# FM33LC0XX register map
File version: 1.0
CPU: SC123, little endian, no MPU, no FPU, 3 interrupt priority bits
Registers are 32-bit, read-write, reset 0x0 unless marked. A register's access mark holds for its fields unless they carry their own. Offsets are from the block's base; [hi:lo] are bit positions; {n}, {i} and the like mark numbered series; 'fields as' and 'values as' point back to an identical list.

## USB — USB module information
Base 0x50000000
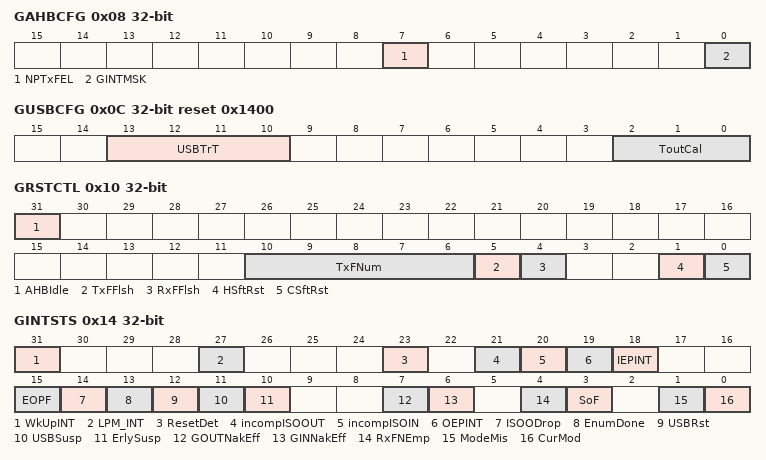
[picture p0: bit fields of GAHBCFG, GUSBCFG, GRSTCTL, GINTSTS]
0x08 GAHBCFG — USB AHB Global Config Register
  [7] NPTxFEL — NPTxFEL field description
  [0] GINTMSK — GINTMSK field description
0x0C GUSBCFG reset 0x1400 — USB Global Config Register
  [13:10] USBTrT — USBTrT field description
  [2:0] ToutCal — ToutCal field description
0x10 GRSTCTL — USB Global Reset Control Register
  [31] AHBIdle — AHBIdle field description
  [10:6] TxFNum — TxFNum field description
  [5] TxFFlsh — TxFFlsh field description
  [4] RxFFlsh — RxFFlsh field description
  [1] HSftRst — HSftRst field description
  [0] CSftRst — CSftRst field description
0x14 GINTSTS — USB Global Interrupt Status Register
  [31] WkUpINT — WkUpINT field description
  [27] LPM_INT — LPM_INT field description
  [23] ResetDet — ResetDet field description
  [21] incompISOOUT — incompISOOUT field description
  [20] incompISOIN — incompISOIN field description
  [19] OEPINT ro — OEPINT field description
  [18] IEPINT ro — IEPINT field description
  [15] EOPF — EOPF field description
  [14] ISOODrop — ISOODrop field description
  [13] EnumDone — EnumDone field description
  [12] USBRst — USBRst field description
  [11] USBSusp — USBSusp field description
  [10] ErlySusp — ErlySusp field description
  [7] GOUTNakEff ro — GOUTNakEff field description
  [6] GINNakEff ro — GINNakEff field description
  [4] RxFNEmp ro — RxFNEmp field description
  [3] SoF — SoF field description
  [1] ModeMis — ModeMis field description
  [0] CurMod ro — CurMod field description
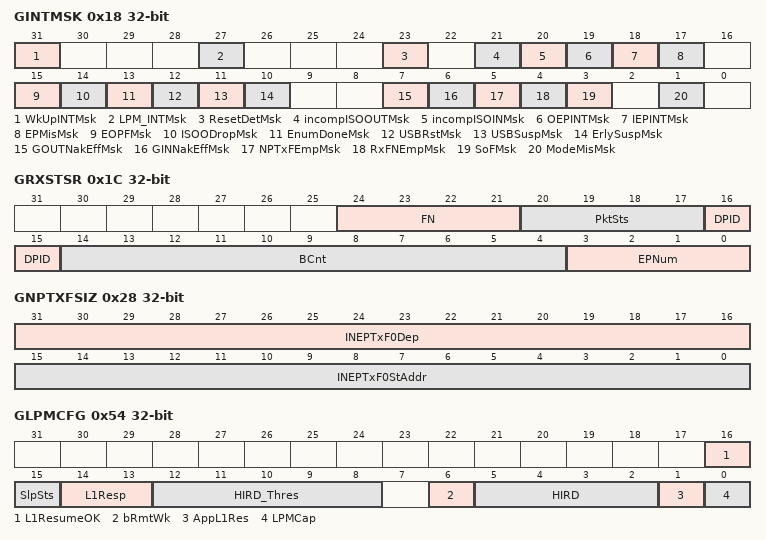
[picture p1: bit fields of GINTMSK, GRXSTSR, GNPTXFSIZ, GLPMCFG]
0x18 GINTMSK — USB Global Interrupt Mask Register
  [31] WkUpINTMsk — WkUpINTMsk field description
  [27] LPM_INTMsk — LPM_INTMsk field description
  [23] ResetDetMsk — ResetDetMsk field description
  [21] incompISOOUTMsk — incompISOOUTMsk field description
  [20] incompISOINMsk — incompISOINMsk field description
  [19] OEPINTMsk — OEPINTMsk field description
  [18] IEPINTMsk — IEPINTMsk field description
  [17] EPMisMsk — EPMisMsk field description
  [15] EOPFMsk — EOPFMsk field description
  [14] ISOODropMsk — ISOODropMsk field description
  [13] EnumDoneMsk — EnumDoneMsk field description
  [12] USBRstMsk — USBRstMsk field description
  [11] USBSuspMsk — USBSuspMsk field description
  [10] ErlySuspMsk — ErlySuspMsk field description
  [7] GOUTNakEffMsk — GOUTNakEffMsk field description
  [6] GINNakEffMsk — GINNakEffMsk field description
  [5] NPTxFEmpMsk — NPTxFEmpMsk field description
  [4] RxFNEmpMsk — RxFNEmpMsk field description
  [3] SoFMsk — SoFMsk field description
  [1] ModeMisMsk — ModeMisMsk field description
0x1C GRXSTSR — USB Receive Status Debug Read Register
  [24:21] FN ro — FN field description
  [20:17] PktSts ro — PktSts field description
  [16:15] DPID ro — DPID field description
  [14:4] BCnt ro — BCnt field description
  [3:0] EPNum ro — EPNum field description
0x24 GRXFSIZ — USB Receive FIFO size Register
  [15:0] RxFDep ro — RxFDep field description
0x28 GNPTXFSIZ — USB Non-Periodic Transmit FIFO size Register
  [31:16] INEPTxF0Dep ro — INEPTxF0Dep field description
  [15:0] INEPTxF0StAddr ro — INEPTxF0StAddr field description
0x54 GLPMCFG — USB Low-Power-Mode config Register
  [16] L1ResumeOK ro — L1ResumeOK field description
  [15] SlpSts ro — SlpSts field description
  [14:13] L1Resp ro — L1Resp field description
  [12:8] HIRD_Thres ro — HIRD_Thres field description
  [6] bRmtWk ro — bRmtWk field description
  [5:2] HIRD ro — HIRD field description
  [1] AppL1Res — AppL1Res field description
  [0] LPMCap — LPMCap field description
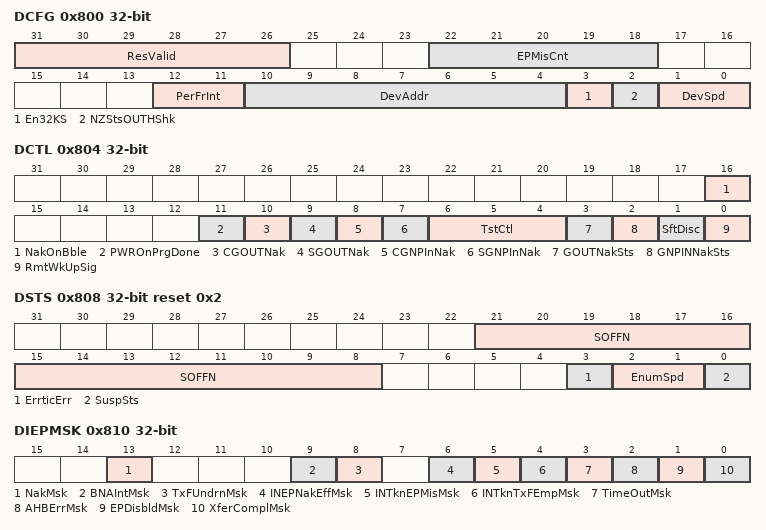
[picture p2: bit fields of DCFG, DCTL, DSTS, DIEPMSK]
0x800 DCFG — USB Device Config Register
  [31:26] ResValid — ResValid field description
  [22:18] EPMisCnt — EPMisCnt field description
  [12:11] PerFrInt — PerFrInt field description
  [10:4] DevAddr — DevAddr field description
  [3] En32KS — En32KS field description
  [2] NZStsOUTHShk — NZStsOUTHShk field description
  [1:0] DevSpd — DevSpd field description
0x804 DCTL — USB Device Control Register
  [16] NakOnBble — NakOnBble field description
  [11] PWROnPrgDone — PWROnPrgDone field description
  [10] CGOUTNak wo — CGOUTNak field description
  [9] SGOUTNak wo — SGOUTNak field description
  [8] CGNPInNak wo — CGNPInNak field description
  [7] SGNPInNak wo — SGNPInNak field description
  [6:4] TstCtl — TstCtl field description
  [3] GOUTNakSts ro — GOUTNakSts field description
  [2] GNPINNakSts ro — GNPINNakSts field description
  [1] SftDisc — SftDisc field description
  [0] RmtWkUpSig — RmtWkUpSig field description
0x808 DSTS reset 0x2 — USB Device Status Register
  [21:8] SOFFN ro — SOFFN field description
  [3] ErrticErr ro — ErrticErr field description
  [2:1] EnumSpd ro — EnumSpd field description
  [0] SuspSts ro — SuspSts field description
0x810 DIEPMSK — USB Device In Endpoint Interrupt Mask Register
  [13] NakMsk — NakMsk field description
  [9] BNAIntMsk — BNAIntMsk field description
  [8] TxFUndrnMsk — TxFUndrnMsk field description
  [6] INEPNakEffMsk — INEPNakEffMsk field description
  [5] INTknEPMisMsk — INTknEPMisMsk field description
  [4] INTknTxFEmpMsk — INTknTxFEmpMsk field description
  [3] TimeOutMsk — TimeOutMsk field description
  [2] AHBErrMsk — AHBErrMsk field description
  [1] EPDisbldMsk — EPDisbldMsk field description
  [0] XferComplMsk — XferComplMsk field description
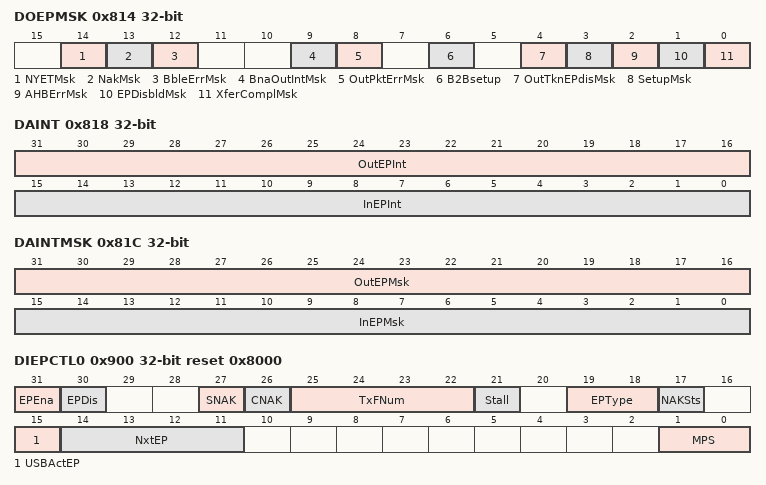
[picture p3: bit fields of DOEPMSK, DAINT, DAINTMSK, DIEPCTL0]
0x814 DOEPMSK — USB Device OUT Endpoint Interrupt Mask Registe
  [14] NYETMsk — NYETMsk field description
  [13] NakMsk — NakMsk field description
  [12] BbleErrMsk — BbleErrMsk field description
  [9] BnaOutIntMsk — BnaOutIntMsk field description
  [8] OutPktErrMsk — OutPktErrMsk field description
  [6] B2Bsetup — B2Bsetup field description
  [4] OutTknEPdisMsk — OutTknEPdisMsk field description
  [3] SetupMsk — SetupMsk field description
  [2] AHBErrMsk — AHBErrMsk field description
  [1] EPDisbldMsk — EPDisbldMsk field description
  [0] XferComplMsk — XferComplMsk field description
0x818 DAINT — USB Device All Endpoint Interrupt Register
  [31:16] OutEPInt ro — OutEPInt field description
  [15:0] InEPInt ro — InEPInt field description
0x81C DAINTMSK — USB Device All Endpoint Interrupt Mask Register
  [31:16] OutEPMsk — OutEPMsk field description
  [15:0] InEPMsk — InEPMsk field description
0x834 DIEPEMPMSK — USB Device IN endpoint FIFO empty interrupt Mask Register
  [2:0] InEpTxfEmpMsk — InEpTxfEmpMsk field description
0x900 DIEPCTL0 reset 0x8000 — USB Device In Endpoint 0 Control Register
  [31] EPEna — EPEna field description
  [30] EPDis — EPDis field description
  [27] SNAK wo — SNAK field description
  [26] CNAK wo — CNAK field description
  [25:22] TxFNum — TxFNum field description
  [21] Stall — Stall field description
  [19:18] EPType ro — EPType field description
  [17] NAKSts ro — NAKSts field description
  [15] USBActEP ro — USBActEP field description
  [14:11] NxtEP — NxtEP field description
  [1:0] MPS — MPS field description
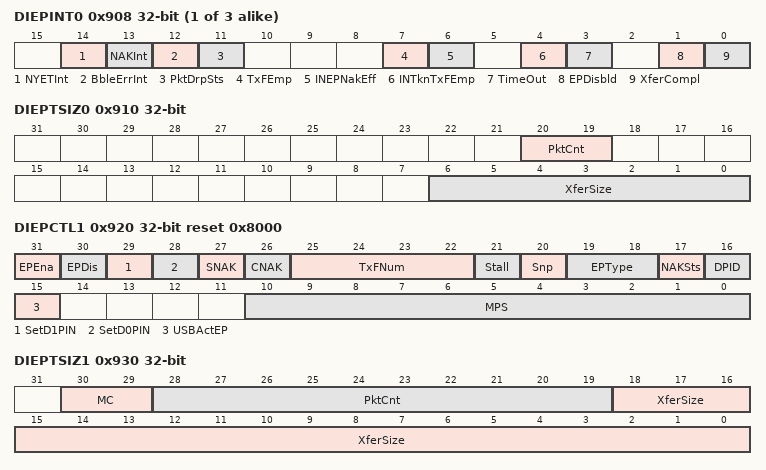
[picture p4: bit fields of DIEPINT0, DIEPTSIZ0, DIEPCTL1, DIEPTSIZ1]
{0x908+0x20*i} DIEPINT{i} (i=0..2) — USB Device In Endpoint {i} Interrupt Register
  [14] NYETInt — NYETInt field description
  [13] NAKInt — NAKInt field description
  [12] BbleErrInt — BbleErrInt field description
  [11] PktDrpSts — PktDrpSts field description
  [7] TxFEmp ro — TxFEmp field description
  [6] INEPNakEff — INEPNakEff field description
  [4] INTknTxFEmp — INTknTxFEmp field description
  [3] TimeOut — TimeOut field description
  [1] EPDisbld — EPDisbld field description
  [0] XferCompl — XferCompl field description
0x910 DIEPTSIZ0 — USB Device IN Endpoint 0 Transfer Size Register
  [20:19] PktCnt — PktCnt field description
  [6:0] XferSize — XferSize field description
{0x918+0x20*i} DTXFSTS{i} (i=0..2) — USB Device In Endpoint {i} Tranmit FIFO Status Register
  [15:0] INEPTxFSpcAvail — INEPTxFSpcAvail field description
0x920 DIEPCTL1 reset 0x8000 — USB Device In Endpoint 1 Control Register
  [31] EPEna — EPEna field description
  [30] EPDis — EPDis field description
  [29] SetD1PIN wo — SetD1PIN field description
  [28] SetD0PIN wo — SetD0PIN field description
  [27] SNAK wo — SNAK field description
  [26] CNAK wo — CNAK field description
  [25:22] TxFNum — TxFNum field description
  [21] Stall — Stall field description
  [20] Snp — Snp field description
  [19:18] EPType — EPType field description
  [17] NAKSts ro — NAKSts field description
  [16] DPID ro — DPID field description
  [15] USBActEP ro — USBActEP field description
  [10:0] MPS — MPS field description
0x930 DIEPTSIZ1 — USB Device IN Endpoint 1 Transfer Size Register
  [30:29] MC — MC field description
  [28:19] PktCnt — PktCnt field description
  [18:0] XferSize — XferSize field description
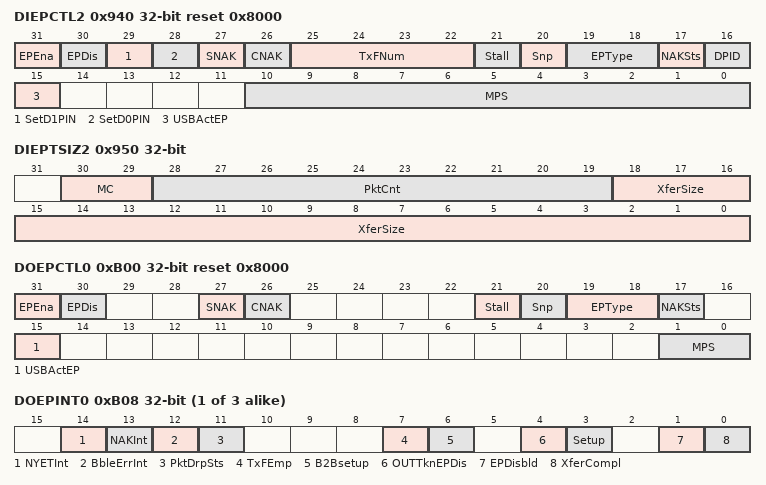
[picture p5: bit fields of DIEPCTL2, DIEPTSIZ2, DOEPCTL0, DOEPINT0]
0x940 DIEPCTL2 reset 0x8000 — USB Device In Endpoint 2 Control Register
  fields as DIEPCTL1
0x950 DIEPTSIZ2 — USB Device IN Endpoint 2 Transfer Size Register
  fields as DIEPTSIZ1
0xB00 DOEPCTL0 reset 0x8000 — USB Device Out Endpoint 0 Control Register
  [31] EPEna — EPEna field description
  [30] EPDis — EPDis field description
  [27] SNAK wo — SNAK field description
  [26] CNAK wo — CNAK field description
  [21] Stall — Stall field description
  [20] Snp — Snp field description
  [19:18] EPType ro — EPType field description
  [17] NAKSts ro — NAKSts field description
  [15] USBActEP ro — USBActEP field description
  [1:0] MPS ro — MPS field description
{0xB08+0x20*i} DOEPINT{i} (i=0..2) — USB Device Out Endpoint {i} Interrupt Register
  [14] NYETInt — NYETInt field description
  [13] NAKInt — NAKInt field description
  [12] BbleErrInt — BbleErrInt field description
  [11] PktDrpSts — PktDrpSts field description
  [7] TxFEmp ro — TxFEmp field description
  [6] B2Bsetup — B2Bsetup field description
  [4] OUTTknEPDis — OUTTknEPDis field description
  [3] Setup — Setup field description
  [1] EPDisbld — EPDisbld field description
  [0] XferCompl — XferCompl field description
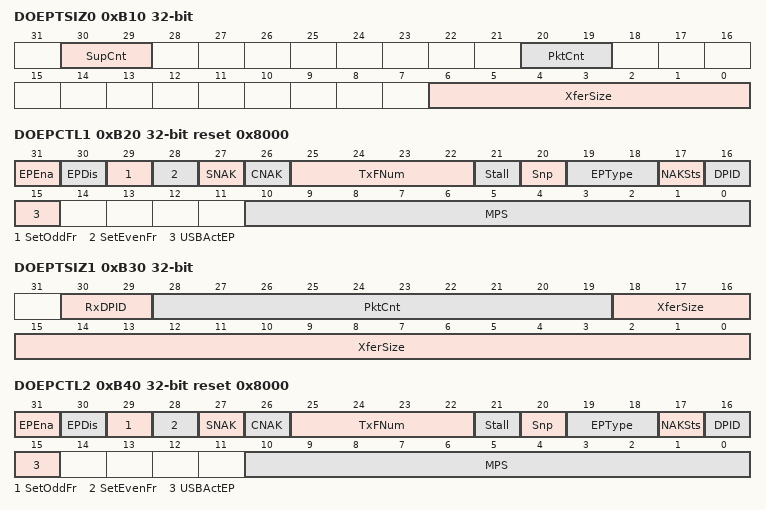
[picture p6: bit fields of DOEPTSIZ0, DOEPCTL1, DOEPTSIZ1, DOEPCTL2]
0xB10 DOEPTSIZ0 — USB Device Out Endpoint 0 Transfer Size Register
  [30:29] SupCnt — SupCnt field description
  [20:19] PktCnt — PktCnt field description
  [6:0] XferSize — XferSize field description
0xB20 DOEPCTL1 reset 0x8000 — USB Device Out Endpoint 1 Control Register
  [31] EPEna — EPEna field description
  [30] EPDis — EPDis field description
  [29] SetOddFr wo — SetOddFr field description
  [28] SetEvenFr wo — SetEvenFr field description
  [27] SNAK wo — SNAK field description
  [26] CNAK wo — CNAK field description
  [25:22] TxFNum — TxFNum field description
  [21] Stall — Stall field description
  [20] Snp — Snp field description
  [19:18] EPType — EPType field description
  [17] NAKSts ro — NAKSts field description
  [16] DPID ro — DPID field description
  [15] USBActEP ro — USBActEP field description
  [10:0] MPS — MPS field description
0xB30 DOEPTSIZ1 — USB Device Out Endpoint 1 Transfer Size Register
  [30:29] RxDPID — RxDPID field description
  [28:19] PktCnt — PktCnt field description
  [18:0] XferSize — XferSize field description
0xB40 DOEPCTL2 reset 0x8000 — USB Device Out Endpoint 2 Control Register
  fields as DOEPCTL1
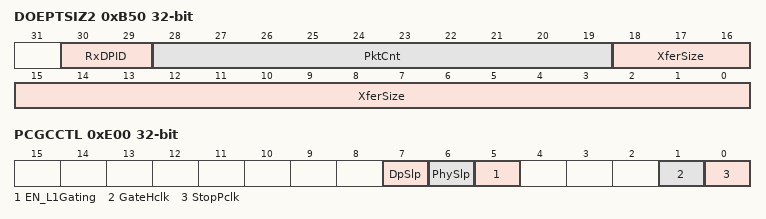
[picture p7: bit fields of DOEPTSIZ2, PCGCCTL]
0xB50 DOEPTSIZ2 — USB Device Out Endpoint 2 Transfer Size Register
  fields as DOEPTSIZ1
0xE00 PCGCCTL — USB Power Control Global Control Register
  [7] DpSlp ro — DpSlp field description
  [6] PhySlp ro — PhySlp field description
  [5] EN_L1Gating — EN_L1Gating field description
  [1] GateHclk — GateHclk field description
  [0] StopPclk — StopPclk field description
